# STM32G070 register map
File version: 1.4
CPU: CM0 r0p1, little endian, MPU, no FPU, 2 interrupt priority bits
Registers are 32-bit, read-write, reset 0x0 unless marked. A register's access mark holds for its fields unless they carry their own. Offsets are from the block's base; [hi:lo] are bit positions; {n}, {i} and the like mark numbered series.

## TAMP — Tamper and backup registers
Base 0x4000B000
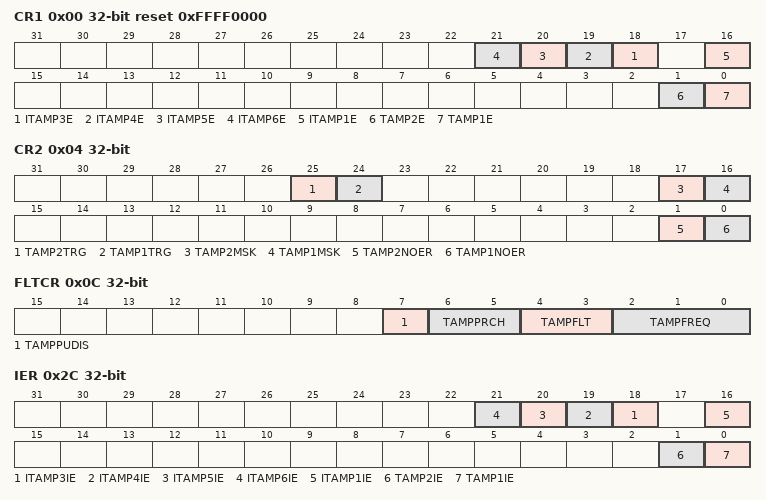
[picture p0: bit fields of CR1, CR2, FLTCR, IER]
0x00 CR1 reset 0xFFFF0000 — control register 1
  [n+15] ITAMP{n}E (n=3..6), [16] ITAMP1E, [1] TAMP2E, [0] TAMP1E
0x04 CR2 — control register 2
  [25] TAMP2TRG, [24] TAMP1TRG, [17] TAMP2MSK, [16] TAMP1MSK, [1] TAMP2NOER, [0] TAMP1NOER
0x0C FLTCR — TAMP filter control register
  [7] TAMPPUDIS, [6:5] TAMPPRCH, [4:3] TAMPFLT, [2:0] TAMPFREQ
0x2C IER — TAMP interrupt enable register
  [n+15] ITAMP{n}IE (n=3..6), [16] ITAMP1IE, [1] TAMP2IE, [0] TAMP1IE
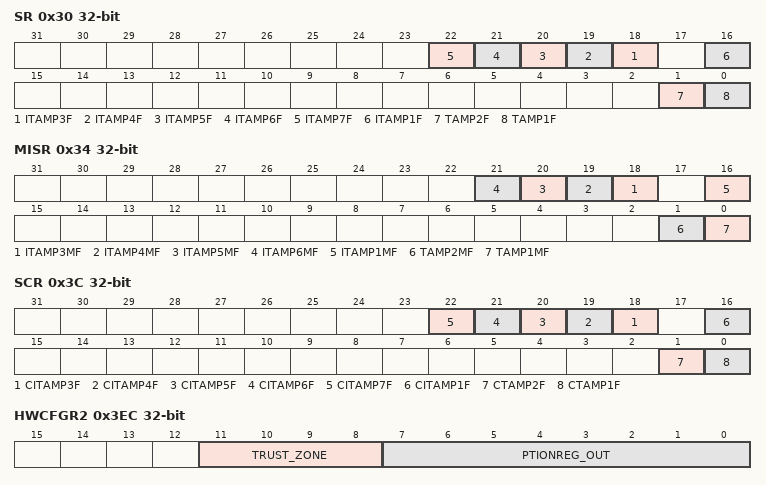
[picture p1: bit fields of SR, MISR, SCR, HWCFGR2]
0x30 SR ro — TAMP status register
  [n+15] ITAMP{n}F (n=3..7), [16] ITAMP1F, [1] TAMP2F, [0] TAMP1F
0x34 MISR ro — TAMP masked interrupt status register
  [n+15] ITAMP{n}MF (n=3..6), [16] ITAMP1MF, [1] TAMP2MF, [0] TAMP1MF
0x3C SCR wo — TAMP status clear register
  [n+15] CITAMP{n}F (n=3..7), [16] CITAMP1F, [1] CTAMP2F, [0] CTAMP1F
{0x100+4i} BKP{i}R (i=0..4) — TAMP backup register
  [31:0] BKP
0x3EC HWCFGR2 ro — TAMP hardware configuration register 2
  [11:8] TRUST_ZONE, [7:0] PTIONREG_OUT
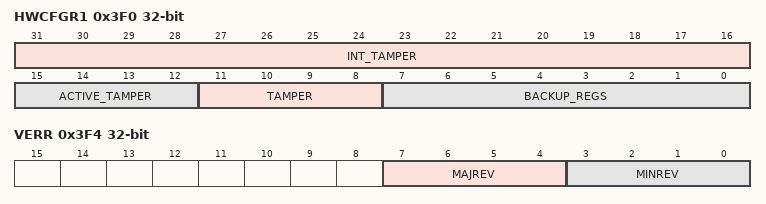
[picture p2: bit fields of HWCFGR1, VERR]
0x3F0 HWCFGR1 ro — TAMP hardware configuration register 1
  [31:16] INT_TAMPER, [15:12] ACTIVE_TAMPER, [11:8] TAMPER, [7:0] BACKUP_REGS
0x3F4 VERR ro — EXTI IP Version register
  [7:4] MAJREV — Major Revision number
  [3:0] MINREV — Minor Revision number
0x3F8 IPIDR ro — EXTI Identification register
  [31:0] IPID — IP Identification
0x3FC SIDR ro — EXTI Size ID register
  [31:0] SID — Size Identification

## TIM14 — General purpose timers
Base 0x40002000
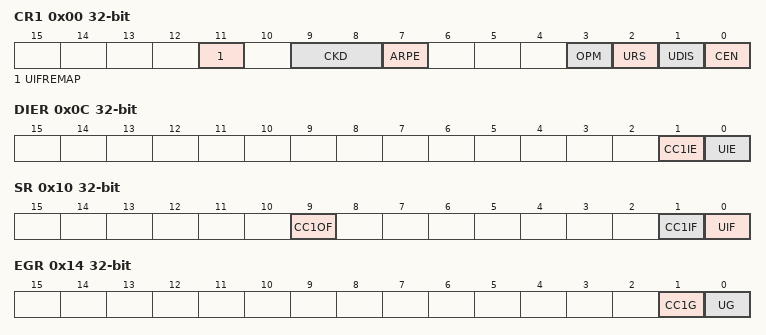
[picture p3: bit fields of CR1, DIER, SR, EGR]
0x00 CR1 — control register 1
  [11] UIFREMAP — UIF status bit remapping
  [9:8] CKD — Clock division
  [7] ARPE — Auto-reload preload enable
  [3] OPM — One-pulse mode
  [2] URS — Update request source
  [1] UDIS — Update disable
  [0] CEN — Counter enable
0x0C DIER — DMA/Interrupt enable register
  [1] CC1IE — Capture/Compare 1 interrupt enable
  [0] UIE — Update interrupt enable
0x10 SR — status register
  [9] CC1OF — Capture/Compare 1 overcapture flag
  [1] CC1IF — Capture/compare 1 interrupt flag
  [0] UIF — Update interrupt flag
0x14 EGR wo — event generation register
  [1] CC1G — Capture/compare 1 generation
  [0] UG — Update generation
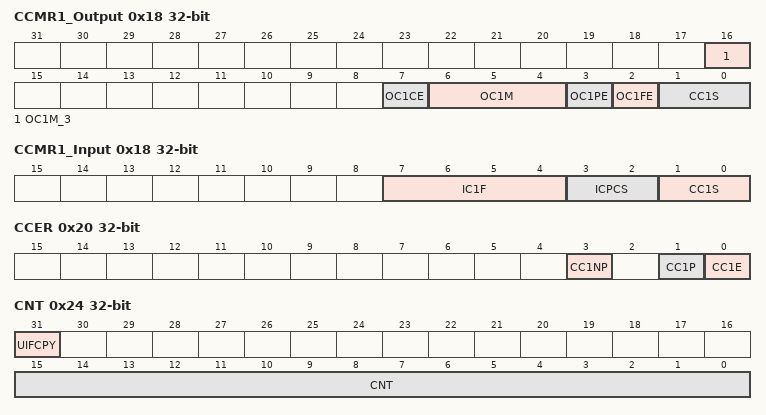
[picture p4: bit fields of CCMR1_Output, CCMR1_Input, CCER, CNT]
0x18 CCMR1_Output — capture/compare mode register 1 (output mode)
  [16] OC1M_3 — Output Compare 1 mode - bit 3
  [7] OC1CE
  [6:4] OC1M
    0=Frozen (The comparison between the output compare register TIMx_CCRy and the counter TIMx_CNT has no effect on the outputs); 1=ActiveOnMatch (Set channel to active level on match. OCyREF signal is forced high when the counter matches the capture/compare register); 2=InactiveOnMatch (Set channel to inactive level on match. OCyREF signal is forced low when the counter matches the capture/compare register); 3=Toggle (OCyREF toggles when TIMx_CNT=TIMx_CCRy); 4=ForceInactive (OCyREF is forced low); 5=ForceActive (OCyREF is forced high); 6=PwmMode1 (In upcounting, channel is active as long as TIMx_CNT<TIMx_CCRy else inactive. In downcounting, channel is inactive as long as TIMx_CNT>TIMx_CCRy else active); 7=PwmMode2 (Inversely to PwmMode1)
  [3] OC1PE
  [2] OC1FE
  [1:0] CC1S
0x18 CCMR1_Input (alternate view of CCMR1_Output) — capture/compare mode register 1 (input mode)
  [7:4] IC1F — Input capture 1 filter
  [3:2] ICPCS — Input capture 1 prescaler
  [1:0] CC1S — Capture/Compare 1 selection
0x20 CCER — capture/compare enable register
  [3] CC1NP — Capture/Compare 1 output Polarity
  [1] CC1P — Capture/Compare 1 output Polarity
  [0] CC1E — Capture/Compare 1 output enable
0x24 CNT — counter
  [31] UIFCPY — UIF Copy
  [15:0] CNT — low counter value
0x28 PSC — prescaler
  [15:0] PSC — Prescaler value
0x2C ARR — auto-reload register
  [15:0] ARR — Low Auto-reload value
0x34 CCR1 — capture/compare register 1
  [15:0] CCR1 — Low Capture/Compare 1 value
0x68 TISEL — TIM timer input selection register
  [3:0] TISEL — TI1[0] to TI1[15] input selection
